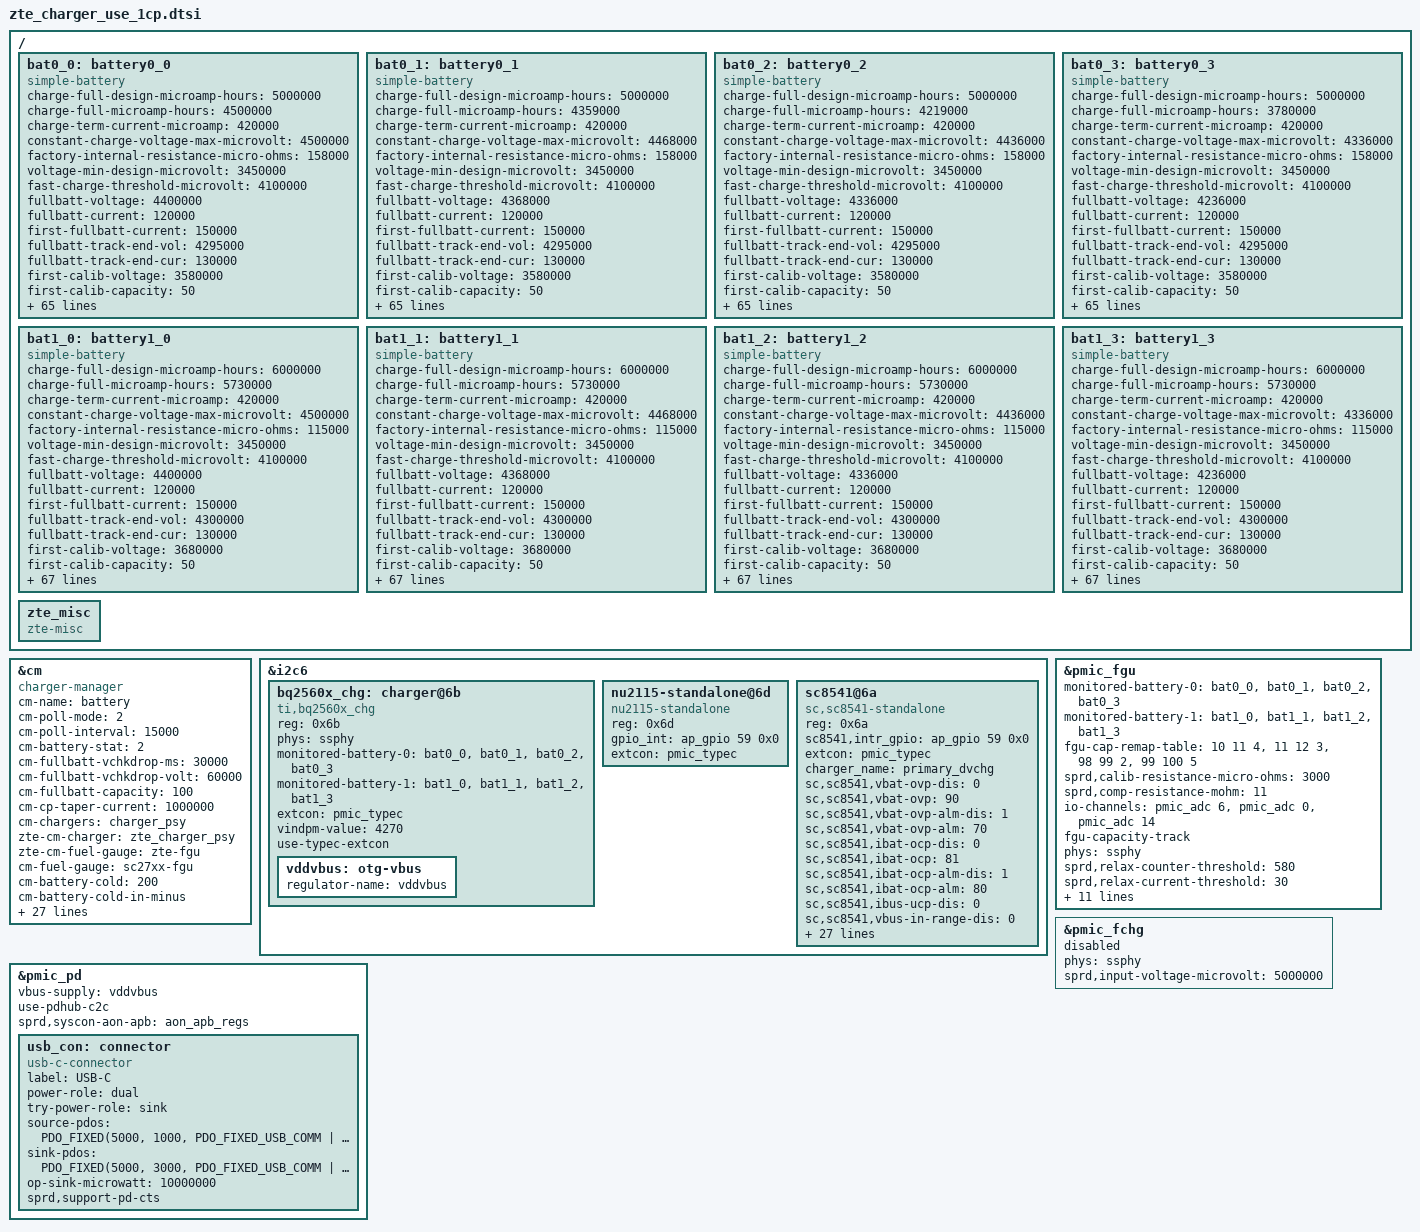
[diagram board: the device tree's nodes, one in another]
#include <dt-bindings/usb/pd.h>


/ {
	bat0_0: battery0_0 {
		compatible = "simple-battery";
		status = "okay";
		charge-full-design-microamp-hours = <5000000>;
		/*Minimum Capacity 4870*0.9 = 4383 4870*0.94 = 4558 4870*0.95 = 4626 4870*0.96 = 4675,4870*0.98 = 4772  we use *0.98 */
		charge-full-microamp-hours = <4772000>;
		charge-term-current-microamp = <420000>;
		constant-charge-voltage-max-microvolt = <4400000>;
		factory-internal-resistance-micro-ohms = <225000>;
		voltage-min-design-microvolt = <3450000>;

		fast-charge-threshold-microvolt = <4100000>;
		fullbatt-voltage = <4300000>;
		fullbatt-current = <120000>;
		first-fullbatt-current = <150000>;
		fullbatt-track-end-vol = <4295000>;
		fullbatt-track-end-cur = <130000>;
		first-calib-voltage = <3580000>;
		first-calib-capacity = <50>;

		ir-cv-offset-microvolt = <100000>;
		ir-rc-micro-ohms = <20000>;
		ir-us-upper-limit-microvolt = <4500000>;

		ocv-capacity-celsius = <20>;
		ocv-capacity-table-0 = <4374000 100>, <4308000 95>, <4250000 90>,
					<4193000 85>, <4139000 80>, <4086000 75>,
					<4037000 70>, <3992000 65>, <3951000 60>,
					<3896000 55>, <3860000 50>, <3836000 45>,
					<3814000 40>, <3797000 35>, <3784000 30>,
					<3767000 25>, <3749000 20>, <3726000 15>,
					<3697000 10>, <3683000 5>, <3400000 0>;
		/* NTC 100k, Vref 1850mV, R pull-up 110K, R pull-down 1000k */
		voltage-temp-table = <1568441 750>, <1534549 800>, <1515014 850>,
					<1475819 900>, <1402274 950>, <1334550 1000>,
					<1222195 1050>, <1131821 1100>, <1035662 1150>,
					<936426 1200>, <837104 1250>, <740441 1300>,
					<648801 1350>, <563916 1400>, <486937 1450>,
					<418193 1500>, <357806 1550>, <305304 1600>,
					<260067 1650>, <221438 1700>, <188468 1750>;
		capacity-temp-table = <25 100>, <10 100>, <0 97>, <(-10) 89>, <(-20) 57>;
		resistance-temp-table = <25 100>, <10 332>, <0 507>, <(-10) 569>, <(-20) 675>;
		charge-sdp-current-microamp = <700000 500000>;
		charge-dcp-current-microamp = <2000000 3000000>;
		charge-cdp-current-microamp = <1500000 1500000>;
		charge-unknown-current-microamp = <1000000 1000000>;
		charge-fchg-current-microamp = <3400000 2000000>;
		charge-flash-current-microamp = <3400000 2700000>;

		cap-calib-energy-density-ocv-table = <3350000 3800000>, <4150000 4350000>;
		cap-track-energy-density-ocv-table = <3400000 3722000>;

		dcp-jeita-temp-table = <1000 1030 0 4400000>,
					<1050 1080 1400000 4400000>,
					<1100 1180 1400000 4400000>,
					<1450 1420 3400000 4400000>,
					<1550 1520 2400000 4100000>;
		sdp-jeita-temp-table = <1000 1030 0 4400000>,
					<1050 1080 1400000 4400000>,
					<1100 1180 1400000 4400000>,
					<1450 1420 3400000 4400000>,
					<1550 1520 2400000 4100000>;
		cdp-jeita-temp-table = <1000 1030 0 4400000>,
					<1050 1080 1400000 4400000>,
					<1100 1180 1400000 4400000>,
					<1450 1420 3400000 4400000>,
					<1550 1520 2400000 4100000>;
		unknown-jeita-temp-table = <1000 1030 0 4400000>,
					<1050 1080 1400000 4400000>,
					<1100 1180 1400000 4400000>,
					<1450 1420 3400000 4400000>,
					<1550 1520 2400000 4100000>;
		fchg-jeita-temp-table = <1000 1030 0 4400000>,
					<1050 1080 1400000 4400000>,
					<1100 1180 1400000 4400000>,
					<1450 1420 3400000 4400000>,
					<1550 1520 2400000 4100000>;
		flash-jeita-temp-table = <1000 1030 0 4400000>,
					<1050 1080 1400000 4400000>,
					<1100 1180 1400000 4400000>,
					<1450 1420 3400000 4400000>,
					<1550 1520 2400000 4100000>;
	};

	bat0_1: battery0_1 {
		compatible = "simple-battery";
		status = "okay";
		charge-full-design-microamp-hours = <5000000>;
		/*Minimum Capacity 4870*0.9 = 4383 4870*0.94 = 4558 4870*0.95 = 4626 4870*0.96 = 4675,4870*0.98 = 4772  we use *0.98 */
		charge-full-microamp-hours = <4772000>;
		charge-term-current-microamp = <420000>;
		constant-charge-voltage-max-microvolt = <4400000>;
		factory-internal-resistance-micro-ohms = <225000>;
		voltage-min-design-microvolt = <3450000>;

		fast-charge-threshold-microvolt = <4100000>;
		fullbatt-voltage = <4300000>;
		fullbatt-current = <120000>;
		first-fullbatt-current = <150000>;
		fullbatt-track-end-vol = <4295000>;
		fullbatt-track-end-cur = <130000>;
		first-calib-voltage = <3580000>;
		first-calib-capacity = <50>;

		ir-cv-offset-microvolt = <100000>;
		ir-rc-micro-ohms = <20000>;
		ir-us-upper-limit-microvolt = <4500000>;

		ocv-capacity-celsius = <20>;
		ocv-capacity-table-0 = <4374000 100>, <4308000 95>, <4250000 90>,
					<4193000 85>, <4139000 80>, <4086000 75>,
					<4037000 70>, <3992000 65>, <3951000 60>,
					<3896000 55>, <3860000 50>, <3836000 45>,
					<3814000 40>, <3797000 35>, <3784000 30>,
					<3767000 25>, <3749000 20>, <3726000 15>,
					<3697000 10>, <3683000 5>, <3400000 0>;
		/* NTC 100k, Vref 1850mV, R pull-up 110K, R pull-down 1000k */
		voltage-temp-table = <1568441 750>, <1534549 800>, <1515014 850>,
					<1475819 900>, <1402274 950>, <1334550 1000>,
					<1222195 1050>, <1131821 1100>, <1035662 1150>,
					<936426 1200>, <837104 1250>, <740441 1300>,
					<648801 1350>, <563916 1400>, <486937 1450>,
					<418193 1500>, <357806 1550>, <305304 1600>,
					<260067 1650>, <221438 1700>, <188468 1750>;
		capacity-temp-table = <25 100>, <10 100>, <0 97>, <(-10) 89>, <(-20) 57>;
		resistance-temp-table = <25 100>, <10 332>, <0 507>, <(-10) 569>, <(-20) 675>;
		charge-sdp-current-microamp = <700000 500000>;
		charge-dcp-current-microamp = <2000000 3000000>;
		charge-cdp-current-microamp = <1500000 1500000>;
		charge-unknown-current-microamp = <1000000 1000000>;
		charge-fchg-current-microamp = <3400000 2000000>;
		charge-flash-current-microamp = <3400000 2700000>;

		cap-calib-energy-density-ocv-table = <3350000 3800000>, <4150000 4350000>;
		cap-track-energy-density-ocv-table = <3400000 3722000>;

		dcp-jeita-temp-table = <1000 1030 0 4400000>,
					<1050 1080 1400000 4400000>,
					<1100 1180 1400000 4400000>,
					<1450 1420 3400000 4400000>,
					<1550 1520 2400000 4100000>;
		sdp-jeita-temp-table = <1000 1030 0 4400000>,
					<1050 1080 1400000 4400000>,
					<1100 1180 1400000 4400000>,
					<1450 1420 3400000 4400000>,
					<1550 1520 2400000 4100000>;
		cdp-jeita-temp-table = <1000 1030 0 4400000>,
					<1050 1080 1400000 4400000>,
					<1100 1180 1400000 4400000>,
					<1450 1420 3400000 4400000>,
					<1550 1520 2400000 4100000>;
		unknown-jeita-temp-table = <1000 1030 0 4400000>,
					<1050 1080 1400000 4400000>,
					<1100 1180 1400000 4400000>,
					<1450 1420 3400000 4400000>,
					<1550 1520 2400000 4100000>;
		fchg-jeita-temp-table = <1000 1030 0 4400000>,
					<1050 1080 1400000 4400000>,
					<1100 1180 1400000 4400000>,
					<1450 1420 3400000 4400000>,
					<1550 1520 2400000 4100000>;
		flash-jeita-temp-table = <1000 1030 0 4400000>,
					<1050 1080 1400000 4400000>,
					<1100 1180 1400000 4400000>,
					<1450 1420 3400000 4400000>,
					<1550 1520 2400000 4100000>;
	};

	bat0_2: battery0_2 {
		compatible = "simple-battery";
		status = "okay";
		charge-full-design-microamp-hours = <5000000>;
		/*Minimum Capacity 4870*0.9 = 4383 4870*0.94 = 4558 4870*0.95 = 4626 4870*0.96 = 4675,4870*0.98 = 4772  we use *0.98 */
		charge-full-microamp-hours = <4772000>;
		charge-term-current-microamp = <420000>;
		constant-charge-voltage-max-microvolt = <4400000>;
		factory-internal-resistance-micro-ohms = <225000>;
		voltage-min-design-microvolt = <3450000>;

		fast-charge-threshold-microvolt = <4100000>;
		fullbatt-voltage = <4300000>;
		fullbatt-current = <120000>;
		first-fullbatt-current = <150000>;
		fullbatt-track-end-vol = <4295000>;
		fullbatt-track-end-cur = <130000>;
		first-calib-voltage = <3580000>;
		first-calib-capacity = <50>;

		ir-cv-offset-microvolt = <100000>;
		ir-rc-micro-ohms = <20000>;
		ir-us-upper-limit-microvolt = <4500000>;

		ocv-capacity-celsius = <20>;
		ocv-capacity-table-0 = <4374000 100>, <4308000 95>, <4250000 90>,
					<4193000 85>, <4139000 80>, <4086000 75>,
					<4037000 70>, <3992000 65>, <3951000 60>,
					<3896000 55>, <3860000 50>, <3836000 45>,
					<3814000 40>, <3797000 35>, <3784000 30>,
					<3767000 25>, <3749000 20>, <3726000 15>,
					<3697000 10>, <3683000 5>, <3400000 0>;
		/* NTC 100k, Vref 1850mV, R pull-up 110K, R pull-down 1000k */
		voltage-temp-table = <1568441 750>, <1534549 800>, <1515014 850>,
					<1475819 900>, <1402274 950>, <1334550 1000>,
					<1222195 1050>, <1131821 1100>, <1035662 1150>,
					<936426 1200>, <837104 1250>, <740441 1300>,
					<648801 1350>, <563916 1400>, <486937 1450>,
					<418193 1500>, <357806 1550>, <305304 1600>,
					<260067 1650>, <221438 1700>, <188468 1750>;
		capacity-temp-table = <25 100>, <10 100>, <0 97>, <(-10) 89>, <(-20) 57>;
		resistance-temp-table = <25 100>, <10 332>, <0 507>, <(-10) 569>, <(-20) 675>;
		charge-sdp-current-microamp = <700000 500000>;
		charge-dcp-current-microamp = <2000000 3000000>;
		charge-cdp-current-microamp = <1500000 1500000>;
		charge-unknown-current-microamp = <1000000 1000000>;
		charge-fchg-current-microamp = <3400000 2000000>;
		charge-flash-current-microamp = <3400000 2700000>;

		cap-calib-energy-density-ocv-table = <3350000 3800000>, <4150000 4350000>;
		cap-track-energy-density-ocv-table = <3400000 3722000>;

		dcp-jeita-temp-table = <1000 1030 0 4400000>,
					<1050 1080 1400000 4400000>,
					<1100 1180 1400000 4400000>,
					<1450 1420 3400000 4400000>,
					<1550 1520 2400000 4100000>;
		sdp-jeita-temp-table = <1000 1030 0 4400000>,
					<1050 1080 1400000 4400000>,
					<1100 1180 1400000 4400000>,
					<1450 1420 3400000 4400000>,
					<1550 1520 2400000 4100000>;
		cdp-jeita-temp-table = <1000 1030 0 4400000>,
					<1050 1080 1400000 4400000>,
					<1100 1180 1400000 4400000>,
					<1450 1420 3400000 4400000>,
					<1550 1520 2400000 4100000>;
		unknown-jeita-temp-table = <1000 1030 0 4400000>,
					<1050 1080 1400000 4400000>,
					<1100 1180 1400000 4400000>,
					<1450 1420 3400000 4400000>,
					<1550 1520 2400000 4100000>;
		fchg-jeita-temp-table = <1000 1030 0 4400000>,
					<1050 1080 1400000 4400000>,
					<1100 1180 1400000 4400000>,
					<1450 1420 3400000 4400000>,
					<1550 1520 2400000 4100000>;
		flash-jeita-temp-table = <1000 1030 0 4400000>,
					<1050 1080 1400000 4400000>,
					<1100 1180 1400000 4400000>,
					<1450 1420 3400000 4400000>,
					<1550 1520 2400000 4100000>;
	};

	bat0_3: battery0_3 {
		compatible = "simple-battery";
		status = "okay";
		charge-full-design-microamp-hours = <5000000>;
		/*Minimum Capacity 4870*0.9 = 4383 4870*0.94 = 4558 4870*0.95 = 4626 4870*0.96 = 4675,4870*0.98 = 4772  we use *0.98 */
		charge-full-microamp-hours = <4772000>;
		charge-term-current-microamp = <420000>;
		constant-charge-voltage-max-microvolt = <4400000>;
		factory-internal-resistance-micro-ohms = <225000>;
		voltage-min-design-microvolt = <3450000>;

		fast-charge-threshold-microvolt = <4100000>;
		fullbatt-voltage = <4300000>;
		fullbatt-current = <120000>;
		first-fullbatt-current = <150000>;
		fullbatt-track-end-vol = <4295000>;
		fullbatt-track-end-cur = <130000>;
		first-calib-voltage = <3580000>;
		first-calib-capacity = <50>;

		ir-cv-offset-microvolt = <100000>;
		ir-rc-micro-ohms = <20000>;
		ir-us-upper-limit-microvolt = <4500000>;

		ocv-capacity-celsius = <20>;
		ocv-capacity-table-0 = <4374000 100>, <4308000 95>, <4250000 90>,
					<4193000 85>, <4139000 80>, <4086000 75>,
					<4037000 70>, <3992000 65>, <3951000 60>,
					<3896000 55>, <3860000 50>, <3836000 45>,
					<3814000 40>, <3797000 35>, <3784000 30>,
					<3767000 25>, <3749000 20>, <3726000 15>,
					<3697000 10>, <3683000 5>, <3400000 0>;
		/* NTC 100k, Vref 1850mV, R pull-up 110K, R pull-down 1000k */
		voltage-temp-table = <1568441 750>, <1534549 800>, <1515014 850>,
					<1475819 900>, <1402274 950>, <1334550 1000>,
					<1222195 1050>, <1131821 1100>, <1035662 1150>,
					<936426 1200>, <837104 1250>, <740441 1300>,
					<648801 1350>, <563916 1400>, <486937 1450>,
					<418193 1500>, <357806 1550>, <305304 1600>,
					<260067 1650>, <221438 1700>, <188468 1750>;
		capacity-temp-table = <25 100>, <10 100>, <0 97>, <(-10) 89>, <(-20) 57>;
		resistance-temp-table = <25 100>, <10 332>, <0 507>, <(-10) 569>, <(-20) 675>;
		charge-sdp-current-microamp = <700000 500000>;
		charge-dcp-current-microamp = <2000000 3000000>;
		charge-cdp-current-microamp = <1500000 1500000>;
		charge-unknown-current-microamp = <1000000 1000000>;
		charge-fchg-current-microamp = <3400000 2000000>;
		charge-flash-current-microamp = <3400000 2700000>;

		cap-calib-energy-density-ocv-table = <3350000 3800000>, <4150000 4350000>;
		cap-track-energy-density-ocv-table = <3400000 3722000>;

		dcp-jeita-temp-table = <1000 1030 0 4400000>,
					<1050 1080 1400000 4400000>,
					<1100 1180 1400000 4400000>,
					<1450 1420 3400000 4400000>,
					<1550 1520 2400000 4100000>;
		sdp-jeita-temp-table = <1000 1030 0 4400000>,
					<1050 1080 1400000 4400000>,
					<1100 1180 1400000 4400000>,
					<1450 1420 3400000 4400000>,
					<1550 1520 2400000 4100000>;
		cdp-jeita-temp-table = <1000 1030 0 4400000>,
					<1050 1080 1400000 4400000>,
					<1100 1180 1400000 4400000>,
					<1450 1420 3400000 4400000>,
					<1550 1520 2400000 4100000>;
		unknown-jeita-temp-table = <1000 1030 0 4400000>,
					<1050 1080 1400000 4400000>,
					<1100 1180 1400000 4400000>,
					<1450 1420 3400000 4400000>,
					<1550 1520 2400000 4100000>;
		fchg-jeita-temp-table = <1000 1030 0 4400000>,
					<1050 1080 1400000 4400000>,
					<1100 1180 1400000 4400000>,
					<1450 1420 3400000 4400000>,
					<1550 1520 2400000 4100000>;
		flash-jeita-temp-table = <1000 1030 0 4400000>,
					<1050 1080 1400000 4400000>,
					<1100 1180 1400000 4400000>,
					<1450 1420 3400000 4400000>,
					<1550 1520 2400000 4100000>;
	};

	bat1_0: battery1_0 {
		compatible = "simple-battery";
		status = "okay";
		charge-full-design-microamp-hours = <5000000>;
		/*Minimum Capacity 4870*0.9 = 4383 4870*0.94 = 4558 4870*0.95 = 4626 4870*0.96 = 4675,4870*0.98 = 4772  we use *0.98 */
		charge-full-microamp-hours = <4772000>;
		charge-term-current-microamp = <420000>;
		constant-charge-voltage-max-microvolt = <4400000>;
		factory-internal-resistance-micro-ohms = <225000>;
		voltage-min-design-microvolt = <3450000>;

		fast-charge-threshold-microvolt = <4100000>;
		fullbatt-voltage = <4300000>;
		fullbatt-current = <120000>;
		first-fullbatt-current = <150000>;
		fullbatt-track-end-vol = <4295000>;
		fullbatt-track-end-cur = <130000>;
		first-calib-voltage = <3580000>;
		first-calib-capacity = <50>;

		ir-cv-offset-microvolt = <100000>;
		ir-rc-micro-ohms = <20000>;
		ir-us-upper-limit-microvolt = <4500000>;

		ocv-capacity-celsius = <20>;
		ocv-capacity-table-0 = <4374000 100>, <4308000 95>, <4250000 90>,
					<4193000 85>, <4139000 80>, <4086000 75>,
					<4037000 70>, <3992000 65>, <3951000 60>,
					<3896000 55>, <3860000 50>, <3836000 45>,
					<3814000 40>, <3797000 35>, <3784000 30>,
					<3767000 25>, <3749000 20>, <3726000 15>,
					<3697000 10>, <3683000 5>, <3400000 0>;
		/* NTC 100k, Vref 1850mV, R pull-up 110K, R pull-down 1000k */
		voltage-temp-table = <1568441 750>, <1534549 800>, <1515014 850>,
					<1475819 900>, <1402274 950>, <1334550 1000>,
					<1222195 1050>, <1131821 1100>, <1035662 1150>,
					<936426 1200>, <837104 1250>, <740441 1300>,
					<648801 1350>, <563916 1400>, <486937 1450>,
					<418193 1500>, <357806 1550>, <305304 1600>,
					<260067 1650>, <221438 1700>, <188468 1750>;
		capacity-temp-table = <25 100>, <10 100>, <0 97>, <(-10) 89>, <(-20) 57>;
		resistance-temp-table = <25 100>, <10 332>, <0 507>, <(-10) 569>, <(-20) 675>;
		charge-sdp-current-microamp = <700000 500000>;
		charge-dcp-current-microamp = <2000000 3000000>;
		charge-cdp-current-microamp = <1500000 1500000>;
		charge-unknown-current-microamp = <1000000 1000000>;
		charge-fchg-current-microamp = <3400000 2000000>;
		charge-flash-current-microamp = <3400000 2700000>;

		cap-calib-energy-density-ocv-table = <3350000 3800000>, <4150000 4350000>;
		cap-track-energy-density-ocv-table = <3400000 3722000>;

		dcp-jeita-temp-table = <1000 1030 0 4400000>,
					<1050 1080 1400000 4400000>,
					<1100 1180 1400000 4400000>,
					<1450 1420 3400000 4400000>,
					<1550 1520 2400000 4100000>;
		sdp-jeita-temp-table = <1000 1030 0 4400000>,
					<1050 1080 1400000 4400000>,
					<1100 1180 1400000 4400000>,
					<1450 1420 3400000 4400000>,
					<1550 1520 2400000 4100000>;
		cdp-jeita-temp-table = <1000 1030 0 4400000>,
					<1050 1080 1400000 4400000>,
					<1100 1180 1400000 4400000>,
					<1450 1420 3400000 4400000>,
					<1550 1520 2400000 4100000>;
		unknown-jeita-temp-table = <1000 1030 0 4400000>,
					<1050 1080 1400000 4400000>,
					<1100 1180 1400000 4400000>,
					<1450 1420 3400000 4400000>,
					<1550 1520 2400000 4100000>;
		fchg-jeita-temp-table = <1000 1030 0 4400000>,
					<1050 1080 1400000 4400000>,
					<1100 1180 1400000 4400000>,
					<1450 1420 3400000 4400000>,
					<1550 1520 2400000 4100000>;
		flash-jeita-temp-table = <1000 1030 0 4400000>,
					<1050 1080 1400000 4400000>,
					<1100 1180 1400000 4400000>,
					<1450 1420 3400000 4400000>,
					<1550 1520 2400000 4100000>;
	};

	bat1_1: battery1_1 {
		compatible = "simple-battery";
		status = "okay";
		charge-full-design-microamp-hours = <5000000>;
		/*Minimum Capacity 4870*0.9 = 4383 4870*0.94 = 4558 4870*0.95 = 4626 4870*0.96 = 4675,4870*0.98 = 4772  we use *0.98 */
		charge-full-microamp-hours = <4772000>;
		charge-term-current-microamp = <420000>;
		constant-charge-voltage-max-microvolt = <4400000>;
		factory-internal-resistance-micro-ohms = <225000>;
		voltage-min-design-microvolt = <3450000>;

		fast-charge-threshold-microvolt = <4100000>;
		fullbatt-voltage = <4300000>;
		fullbatt-current = <120000>;
		first-fullbatt-current = <150000>;
		fullbatt-track-end-vol = <4295000>;
		fullbatt-track-end-cur = <130000>;
		first-calib-voltage = <3580000>;
		first-calib-capacity = <50>;

		ir-cv-offset-microvolt = <100000>;
		ir-rc-micro-ohms = <20000>;
		ir-us-upper-limit-microvolt = <4500000>;

		ocv-capacity-celsius = <20>;
		ocv-capacity-table-0 = <4374000 100>, <4308000 95>, <4250000 90>,
					<4193000 85>, <4139000 80>, <4086000 75>,
					<4037000 70>, <3992000 65>, <3951000 60>,
					<3896000 55>, <3860000 50>, <3836000 45>,
					<3814000 40>, <3797000 35>, <3784000 30>,
					<3767000 25>, <3749000 20>, <3726000 15>,
					<3697000 10>, <3683000 5>, <3400000 0>;
		/* NTC 100k, Vref 1850mV, R pull-up 110K, R pull-down 1000k */
		voltage-temp-table = <1568441 750>, <1534549 800>, <1515014 850>,
					<1475819 900>, <1402274 950>, <1334550 1000>,
					<1222195 1050>, <1131821 1100>, <1035662 1150>,
					<936426 1200>, <837104 1250>, <740441 1300>,
					<648801 1350>, <563916 1400>, <486937 1450>,
					<418193 1500>, <357806 1550>, <305304 1600>,
					<260067 1650>, <221438 1700>, <188468 1750>;
		capacity-temp-table = <25 100>, <10 100>, <0 97>, <(-10) 89>, <(-20) 57>;
		resistance-temp-table = <25 100>, <10 332>, <0 507>, <(-10) 569>, <(-20) 675>;
		charge-sdp-current-microamp = <700000 500000>;
		charge-dcp-current-microamp = <2000000 3000000>;
		charge-cdp-current-microamp = <1500000 1500000>;
		charge-unknown-current-microamp = <1000000 1000000>;
		charge-fchg-current-microamp = <3400000 2000000>;
		charge-flash-current-microamp = <3400000 2700000>;

		cap-calib-energy-density-ocv-table = <3350000 3800000>, <4150000 4350000>;
		cap-track-energy-density-ocv-table = <3400000 3722000>;

		dcp-jeita-temp-table = <1000 1030 0 4400000>,
					<1050 1080 1400000 4400000>,
					<1100 1180 1400000 4400000>,
					<1450 1420 3400000 4400000>,
					<1550 1520 2400000 4100000>;
		sdp-jeita-temp-table = <1000 1030 0 4400000>,
					<1050 1080 1400000 4400000>,
					<1100 1180 1400000 4400000>,
					<1450 1420 3400000 4400000>,
					<1550 1520 2400000 4100000>;
		cdp-jeita-temp-table = <1000 1030 0 4400000>,
					<1050 1080 1400000 4400000>,
					<1100 1180 1400000 4400000>,
					<1450 1420 3400000 4400000>,
					<1550 1520 2400000 4100000>;
		unknown-jeita-temp-table = <1000 1030 0 4400000>,
					<1050 1080 1400000 4400000>,
					<1100 1180 1400000 4400000>,
					<1450 1420 3400000 4400000>,
					<1550 1520 2400000 4100000>;
		fchg-jeita-temp-table = <1000 1030 0 4400000>,
					<1050 1080 1400000 4400000>,
					<1100 1180 1400000 4400000>,
					<1450 1420 3400000 4400000>,
					<1550 1520 2400000 4100000>;
		flash-jeita-temp-table = <1000 1030 0 4400000>,
					<1050 1080 1400000 4400000>,
					<1100 1180 1400000 4400000>,
					<1450 1420 3400000 4400000>,
					<1550 1520 2400000 4100000>;
	};

	bat1_2: battery1_2 {
		compatible = "simple-battery";
		status = "okay";
		charge-full-design-microamp-hours = <5000000>;
		/*Minimum Capacity 4870*0.9 = 4383 4870*0.94 = 4558 4870*0.95 = 4626 4870*0.96 = 4675,4870*0.98 = 4772  we use *0.98 */
		charge-full-microamp-hours = <4772000>;
		charge-term-current-microamp = <420000>;
		constant-charge-voltage-max-microvolt = <4400000>;
		factory-internal-resistance-micro-ohms = <225000>;
		voltage-min-design-microvolt = <3450000>;

		fast-charge-threshold-microvolt = <4100000>;
		fullbatt-voltage = <4300000>;
		fullbatt-current = <120000>;
		first-fullbatt-current = <150000>;
		fullbatt-track-end-vol = <4295000>;
		fullbatt-track-end-cur = <130000>;
		first-calib-voltage = <3580000>;
		first-calib-capacity = <50>;

		ir-cv-offset-microvolt = <100000>;
		ir-rc-micro-ohms = <20000>;
		ir-us-upper-limit-microvolt = <4500000>;

		ocv-capacity-celsius = <20>;
		ocv-capacity-table-0 = <4374000 100>, <4308000 95>, <4250000 90>,
					<4193000 85>, <4139000 80>, <4086000 75>,
					<4037000 70>, <3992000 65>, <3951000 60>,
					<3896000 55>, <3860000 50>, <3836000 45>,
					<3814000 40>, <3797000 35>, <3784000 30>,
					<3767000 25>, <3749000 20>, <3726000 15>,
					<3697000 10>, <3683000 5>, <3400000 0>;
		/* NTC 100k, Vref 1850mV, R pull-up 110K, R pull-down 1000k */
		voltage-temp-table = <1568441 750>, <1534549 800>, <1515014 850>,
					<1475819 900>, <1402274 950>, <1334550 1000>,
					<1222195 1050>, <1131821 1100>, <1035662 1150>,
					<936426 1200>, <837104 1250>, <740441 1300>,
					<648801 1350>, <563916 1400>, <486937 1450>,
					<418193 1500>, <357806 1550>, <305304 1600>,
					<260067 1650>, <221438 1700>, <188468 1750>;
		capacity-temp-table = <25 100>, <10 100>, <0 97>, <(-10) 89>, <(-20) 57>;
		resistance-temp-table = <25 100>, <10 332>, <0 507>, <(-10) 569>, <(-20) 675>;
		charge-sdp-current-microamp = <700000 500000>;
		charge-dcp-current-microamp = <2000000 3000000>;
		charge-cdp-current-microamp = <1500000 1500000>;
		charge-unknown-current-microamp = <1000000 1000000>;
		charge-fchg-current-microamp = <3400000 2000000>;
		charge-flash-current-microamp = <3400000 2700000>;

		cap-calib-energy-density-ocv-table = <3350000 3800000>, <4150000 4350000>;
		cap-track-energy-density-ocv-table = <3400000 3722000>;

		dcp-jeita-temp-table = <1000 1030 0 4400000>,
					<1050 1080 1400000 4400000>,
					<1100 1180 1400000 4400000>,
					<1450 1420 3400000 4400000>,
					<1550 1520 2400000 4100000>;
		sdp-jeita-temp-table = <1000 1030 0 4400000>,
					<1050 1080 1400000 4400000>,
					<1100 1180 1400000 4400000>,
					<1450 1420 3400000 4400000>,
					<1550 1520 2400000 4100000>;
		cdp-jeita-temp-table = <1000 1030 0 4400000>,
					<1050 1080 1400000 4400000>,
					<1100 1180 1400000 4400000>,
					<1450 1420 3400000 4400000>,
					<1550 1520 2400000 4100000>;
		unknown-jeita-temp-table = <1000 1030 0 4400000>,
					<1050 1080 1400000 4400000>,
					<1100 1180 1400000 4400000>,
					<1450 1420 3400000 4400000>,
					<1550 1520 2400000 4100000>;
		fchg-jeita-temp-table = <1000 1030 0 4400000>,
					<1050 1080 1400000 4400000>,
					<1100 1180 1400000 4400000>,
					<1450 1420 3400000 4400000>,
					<1550 1520 2400000 4100000>;
		flash-jeita-temp-table = <1000 1030 0 4400000>,
					<1050 1080 1400000 4400000>,
					<1100 1180 1400000 4400000>,
					<1450 1420 3400000 4400000>,
					<1550 1520 2400000 4100000>;
	};

	bat1_3: battery1_3 {
		compatible = "simple-battery";
		status = "okay";
		charge-full-design-microamp-hours = <5000000>;
		/*Minimum Capacity 4870*0.9 = 4383 4870*0.94 = 4558 4870*0.95 = 4626 4870*0.96 = 4675,4870*0.98 = 4772  we use *0.98 */
		charge-full-microamp-hours = <4772000>;
		charge-term-current-microamp = <420000>;
		constant-charge-voltage-max-microvolt = <4400000>;
		factory-internal-resistance-micro-ohms = <225000>;
		voltage-min-design-microvolt = <3450000>;

		fast-charge-threshold-microvolt = <4100000>;
		fullbatt-voltage = <4300000>;
		fullbatt-current = <120000>;
		first-fullbatt-current = <150000>;
		fullbatt-track-end-vol = <4295000>;
		fullbatt-track-end-cur = <130000>;
		first-calib-voltage = <3580000>;
		first-calib-capacity = <50>;

		ir-cv-offset-microvolt = <100000>;
		ir-rc-micro-ohms = <20000>;
		ir-us-upper-limit-microvolt = <4500000>;

		ocv-capacity-celsius = <20>;
		ocv-capacity-table-0 = <4374000 100>, <4308000 95>, <4250000 90>,
					<4193000 85>, <4139000 80>, <4086000 75>,
					<4037000 70>, <3992000 65>, <3951000 60>,
					<3896000 55>, <3860000 50>, <3836000 45>,
					<3814000 40>, <3797000 35>, <3784000 30>,
					<3767000 25>, <3749000 20>, <3726000 15>,
					<3697000 10>, <3683000 5>, <3400000 0>;
		/* NTC 100k, Vref 1850mV, R pull-up 110K, R pull-down 1000k */
		voltage-temp-table = <1568441 750>, <1534549 800>, <1515014 850>,
					<1475819 900>, <1402274 950>, <1334550 1000>,
					<1222195 1050>, <1131821 1100>, <1035662 1150>,
					<936426 1200>, <837104 1250>, <740441 1300>,
					<648801 1350>, <563916 1400>, <486937 1450>,
					<418193 1500>, <357806 1550>, <305304 1600>,
					<260067 1650>, <221438 1700>, <188468 1750>;
		capacity-temp-table = <25 100>, <10 100>, <0 97>, <(-10) 89>, <(-20) 57>;
		resistance-temp-table = <25 100>, <10 332>, <0 507>, <(-10) 569>, <(-20) 675>;
		charge-sdp-current-microamp = <700000 500000>;
		charge-dcp-current-microamp = <2000000 3000000>;
		charge-cdp-current-microamp = <1500000 1500000>;
		charge-unknown-current-microamp = <1000000 1000000>;
		charge-fchg-current-microamp = <3400000 2000000>;
		charge-flash-current-microamp = <3400000 2700000>;

		cap-calib-energy-density-ocv-table = <3350000 3800000>, <4150000 4350000>;
		cap-track-energy-density-ocv-table = <3400000 3722000>;

		dcp-jeita-temp-table = <1000 1030 0 4400000>,
					<1050 1080 1400000 4400000>,
					<1100 1180 1400000 4400000>,
					<1450 1420 3400000 4400000>,
					<1550 1520 2400000 4100000>;
		sdp-jeita-temp-table = <1000 1030 0 4400000>,
					<1050 1080 1400000 4400000>,
					<1100 1180 1400000 4400000>,
					<1450 1420 3400000 4400000>,
					<1550 1520 2400000 4100000>;
		cdp-jeita-temp-table = <1000 1030 0 4400000>,
					<1050 1080 1400000 4400000>,
					<1100 1180 1400000 4400000>,
					<1450 1420 3400000 4400000>,
					<1550 1520 2400000 4100000>;
		unknown-jeita-temp-table = <1000 1030 0 4400000>,
					<1050 1080 1400000 4400000>,
					<1100 1180 1400000 4400000>,
					<1450 1420 3400000 4400000>,
					<1550 1520 2400000 4100000>;
		fchg-jeita-temp-table = <1000 1030 0 4400000>,
					<1050 1080 1400000 4400000>,
					<1100 1180 1400000 4400000>,
					<1450 1420 3400000 4400000>,
					<1550 1520 2400000 4100000>;
		flash-jeita-temp-table = <1000 1030 0 4400000>,
					<1050 1080 1400000 4400000>,
					<1100 1180 1400000 4400000>,
					<1450 1420 3400000 4400000>,
					<1550 1520 2400000 4100000>;
	};
};

&bat0_0 {
	compatible = "simple-battery";
	status = "okay";
	charge-full-design-microamp-hours = <5000000>;
	/*Minimum Capacity origin min cap is 4930, 4930*0.91 = 4500*/
	charge-full-microamp-hours = <4500000>;
	charge-term-current-microamp = <420000>;
	constant-charge-voltage-max-microvolt = <4500000>;
	factory-internal-resistance-micro-ohms = <158000>;
	voltage-min-design-microvolt = <3450000>;

	fast-charge-threshold-microvolt = <4100000>;
	fullbatt-voltage = <4400000>;
	fullbatt-current = <120000>;
	first-fullbatt-current = <150000>;
	fullbatt-track-end-vol = <4295000>;
	fullbatt-track-end-cur = <130000>;
	first-calib-voltage = <3580000>;
	first-calib-capacity = <50>;

	ir-cv-offset-microvolt = <100000>;
	ir-rc-micro-ohms = <20000>;
	ir-us-upper-limit-microvolt = <4500000>;

	batt-id-list = <110 430>;  /* kohm,  scud 5000mAh/highpower 6000mAh*/
	ocv-capacity-celsius = <20>;
	ocv-capacity-table-0 = <4425000 100>, <4368000 95>, <4315000 90>,
				<4257000 85>, <4197000 80>, <4138000 75>,
				<4083000 70>, <4032000 65>, <3985000 60>,
				<3922000 55>, <3880000 50>, <3850000 45>,
				<3827000 40>, <3808000 35>, <3792000 30>,
				<3771000 25>, <3749000 20>, <3723000 15>,
				<3692000 10>, <3682000 5>, <3400000 0>;
	/* NTC 100k, Vref 1850mV, R pull-up 110K, R pull-down 1000k */
	voltage-temp-table = <1568441 750>, <1534549 800>, <1515014 850>,
				<1475819 900>, <1402274 950>, <1334550 1000>,
				<1222195 1050>, <1131821 1100>, <1035662 1150>,
				<936426 1200>, <837104 1250>, <740441 1300>,
				<648801 1350>, <563916 1400>, <486937 1450>,
				<418193 1500>, <357806 1550>, <305304 1600>,
				<260067 1650>, <221438 1700>, <188468 1750>;
	capacity-temp-table = <25 100>, <10 100>, <0 90>, <(-10) 81>, <(-20) 62>;
	resistance-temp-table = <25 100>, <10 233>, <0 746>, <(-10) 824>, <(-20) 913>;
	charge-sdp-current-microamp = <700000 500000>;
	charge-dcp-current-microamp = <6500000 3000000>;
	charge-cdp-current-microamp = <4800000 1500000>;
	charge-unknown-current-microamp = <1000000 1000000>;
	charge-fchg-current-microamp = <6500000 4000000>;
	charge-flash-current-microamp = <6500000 4000000>;

	cap-calib-energy-density-ocv-table = <3350000 3800000>, <4150000 4400000>;
	cap-track-energy-density-ocv-table = <3400000 3722000>;

	dcp-jeita-temp-table = <1000 1030 0 4450000>,
				<1050 1080 1461000 4450000>,
				<1150 1180 4800000 4450000>,
				<1450 1420 6500000 4450000>,
				<1550 1520 2435000 4100000>;
	sdp-jeita-temp-table = <1000 1030 0 4450000>,
				<1050 1080 1461000 4450000>,
				<1150 1180 4800000 4450000>,
				<1450 1420 6500000 4450000>,
				<1550 1520 2435000 4100000>;
	cdp-jeita-temp-table = <1000 1030 0 4450000>,
				<1050 1080 1461000 4450000>,
				<1150 1180 4800000 4450000>,
				<1450 1420 6500000 4450000>,
				<1550 1520 2435000 4100000>;
	unknown-jeita-temp-table = <1000 1030 0 4450000>,
				<1050 1080 1461000 4450000>,
				<1150 1180 4800000 4450000>,
				<1450 1420 6500000 4450000>,
				<1550 1520 2435000 4100000>;

	fchg-jeita-temp-table = <1000 1030 0 4450000>,
				<1050 1080 1461000 4450000>,
				<1150 1180 4800000 4450000>,
				<1450 1420 6500000 4450000>,
				<1550 1520 2435000 4100000>;
	flash-jeita-temp-table = <1000 1030 0 4450000>,
				<1050 1080 1461000 4450000>,
				<1150 1180 4800000 4450000>,
				<1450 1420 6500000 4450000>,
				<1550 1520 2435000 4100000>;

};

&bat0_1 {
	compatible = "simple-battery";
	status = "okay";
	charge-full-design-microamp-hours = <5000000>;
	/*Minimum Capacity origin min cap is 4930, 4930*0.91 = 4500*/
	charge-full-microamp-hours = <4359000>;
	charge-term-current-microamp = <420000>;
	constant-charge-voltage-max-microvolt = <4468000>;
	factory-internal-resistance-micro-ohms = <158000>;
	voltage-min-design-microvolt = <3450000>;

	fast-charge-threshold-microvolt = <4100000>;
	fullbatt-voltage = <4368000>;
	fullbatt-current = <120000>;
	first-fullbatt-current = <150000>;
	fullbatt-track-end-vol = <4295000>;
	fullbatt-track-end-cur = <130000>;
	first-calib-voltage = <3580000>;
	first-calib-capacity = <50>;

	ir-cv-offset-microvolt = <100000>;
	ir-rc-micro-ohms = <20000>;
	ir-us-upper-limit-microvolt = <4500000>;

	batt-id-list = <110 430>;  /* kohm,  scud 5000mAh/highpower 6000mAh*/
	ocv-capacity-celsius = <20>;
	ocv-capacity-table-0 = <4393000 100>, <4338000 95>, <4286000 90>,
				<4230000 85>, <4172000 80>, <4114000 75>,
				<4061000 70>, <4012000 65>, <3966000 60>,
				<3905000 55>, <3865000 50>, <3835000 45>,
				<3813000 40>, <3795000 35>, <3779000 30>,
				<3759000 25>, <3738000 20>, <3712000 15>,
				<3682000 10>, <3663000 5>, <3400000 0>;
	/* NTC 100k, Vref 1850mV, R pull-up 110K, R pull-down 1000k */
	voltage-temp-table = <1568441 750>, <1534549 800>, <1515014 850>,
				<1475819 900>, <1402274 950>, <1334550 1000>,
				<1222195 1050>, <1131821 1100>, <1035662 1150>,
				<936426 1200>, <837104 1250>, <740441 1300>,
				<648801 1350>, <563916 1400>, <486937 1450>,
				<418193 1500>, <357806 1550>, <305304 1600>,
				<260067 1650>, <221438 1700>, <188468 1750>;
	capacity-temp-table = <25 100>, <10 100>, <0 90>, <(-10) 81>, <(-20) 62>;
	resistance-temp-table = <25 100>, <10 233>, <0 746>, <(-10) 824>, <(-20) 913>;
	charge-sdp-current-microamp = <700000 500000>;
	charge-dcp-current-microamp = <6500000 3000000>;
	charge-cdp-current-microamp = <4800000 1500000>;
	charge-unknown-current-microamp = <1000000 1000000>;
	charge-fchg-current-microamp = <6500000 4000000>;
	charge-flash-current-microamp = <6500000 4000000>;

	cap-calib-energy-density-ocv-table = <3350000 3800000>, <4150000 4400000>;
	cap-track-energy-density-ocv-table = <3400000 3722000>;

	dcp-jeita-temp-table = <1000 1030 0 4450000>,
				<1050 1080 1461000 4450000>,
				<1150 1180 4800000 4450000>,
				<1450 1420 6500000 4450000>,
				<1550 1520 2435000 4100000>;
	sdp-jeita-temp-table = <1000 1030 0 4450000>,
				<1050 1080 1461000 4450000>,
				<1150 1180 4800000 4450000>,
				<1450 1420 6500000 4450000>,
				<1550 1520 2435000 4100000>;
	cdp-jeita-temp-table = <1000 1030 0 4450000>,
				<1050 1080 1461000 4450000>,
				<1150 1180 4800000 4450000>,
				<1450 1420 6500000 4450000>,
				<1550 1520 2435000 4100000>;
	unknown-jeita-temp-table = <1000 1030 0 4450000>,
				<1050 1080 1461000 4450000>,
				<1150 1180 4800000 4450000>,
				<1450 1420 6500000 4450000>,
				<1550 1520 2435000 4100000>;

	fchg-jeita-temp-table = <1000 1030 0 4450000>,
				<1050 1080 1461000 4450000>,
				<1150 1180 4800000 4450000>,
				<1450 1420 6500000 4450000>,
				<1550 1520 2435000 4100000>;
	flash-jeita-temp-table = <1000 1030 0 4450000>,
				<1050 1080 1461000 4450000>,
				<1150 1180 4800000 4450000>,
				<1450 1420 6500000 4450000>,
				<1550 1520 2435000 4100000>;

};

&bat0_2 {
	compatible = "simple-battery";
	status = "okay";
	charge-full-design-microamp-hours = <5000000>;
	/*Minimum Capacity origin min cap is 4930, 4930*0.91 = 4500*/
	charge-full-microamp-hours = <4219000>;
	charge-term-current-microamp = <420000>;
	constant-charge-voltage-max-microvolt = <4436000>;
	factory-internal-resistance-micro-ohms = <158000>;
	voltage-min-design-microvolt = <3450000>;

	fast-charge-threshold-microvolt = <4100000>;
	fullbatt-voltage = <4336000>;
	fullbatt-current = <120000>;
	first-fullbatt-current = <150000>;
	fullbatt-track-end-vol = <4295000>;
	fullbatt-track-end-cur = <130000>;
	first-calib-voltage = <3580000>;
	first-calib-capacity = <50>;

	ir-cv-offset-microvolt = <100000>;
	ir-rc-micro-ohms = <20000>;
	ir-us-upper-limit-microvolt = <4500000>;

	batt-id-list = <110 430>;  /* kohm,  scud 5000mAh/highpower 6000mAh*/
	ocv-capacity-celsius = <20>;
	ocv-capacity-table-0 = <4361000 100>, <4307000 95>, <4257000 90>,
				<4203000 85>, <4147000 80>, <4091000 75>,
				<4040000 70>, <3992000 65>, <3948000 60>,
				<3889000 55>, <3850000 50>, <3821000 45>,
				<3800000 40>, <3782000 35>, <3767000 30>,
				<3747000 25>, <3727000 20>, <3702000 15>,
				<3673000 10>, <3664000 5>, <3400000 0>;
	/* NTC 100k, Vref 1850mV, R pull-up 110K, R pull-down 1000k */
	voltage-temp-table = <1568441 750>, <1534549 800>, <1515014 850>,
				<1475819 900>, <1402274 950>, <1334550 1000>,
				<1222195 1050>, <1131821 1100>, <1035662 1150>,
				<936426 1200>, <837104 1250>, <740441 1300>,
				<648801 1350>, <563916 1400>, <486937 1450>,
				<418193 1500>, <357806 1550>, <305304 1600>,
				<260067 1650>, <221438 1700>, <188468 1750>;
	capacity-temp-table = <25 100>, <10 100>, <0 90>, <(-10) 81>, <(-20) 62>;
	resistance-temp-table = <25 100>, <10 233>, <0 746>, <(-10) 824>, <(-20) 913>;
	charge-sdp-current-microamp = <700000 500000>;
	charge-dcp-current-microamp = <6500000 3000000>;
	charge-cdp-current-microamp = <4800000 1500000>;
	charge-unknown-current-microamp = <1000000 1000000>;
	charge-fchg-current-microamp = <6500000 4000000>;
	charge-flash-current-microamp = <6500000 4000000>;

	cap-calib-energy-density-ocv-table = <3350000 3800000>, <4150000 4400000>;
	cap-track-energy-density-ocv-table = <3400000 3722000>;

	dcp-jeita-temp-table = <1000 1030 0 4450000>,
				<1050 1080 1461000 4450000>,
				<1150 1180 4800000 4450000>,
				<1450 1420 6500000 4450000>,
				<1550 1520 2435000 4100000>;
	sdp-jeita-temp-table = <1000 1030 0 4450000>,
				<1050 1080 1461000 4450000>,
				<1150 1180 4800000 4450000>,
				<1450 1420 6500000 4450000>,
				<1550 1520 2435000 4100000>;
	cdp-jeita-temp-table = <1000 1030 0 4450000>,
				<1050 1080 1461000 4450000>,
				<1150 1180 4800000 4450000>,
				<1450 1420 6500000 4450000>,
				<1550 1520 2435000 4100000>;
	unknown-jeita-temp-table = <1000 1030 0 4450000>,
				<1050 1080 1461000 4450000>,
				<1150 1180 4800000 4450000>,
				<1450 1420 6500000 4450000>,
				<1550 1520 2435000 4100000>;

	fchg-jeita-temp-table = <1000 1030 0 4450000>,
				<1050 1080 1461000 4450000>,
				<1150 1180 4800000 4450000>,
				<1450 1420 6500000 4450000>,
				<1550 1520 2435000 4100000>;
	flash-jeita-temp-table = <1000 1030 0 4450000>,
				<1050 1080 1461000 4450000>,
				<1150 1180 4800000 4450000>,
				<1450 1420 6500000 4450000>,
				<1550 1520 2435000 4100000>;

};

&bat0_3 {
	compatible = "simple-battery";
	status = "okay";
	charge-full-design-microamp-hours = <5000000>;
	/*Minimum Capacity origin min cap is 4930, 4930*0.91 = 4500*/
	charge-full-microamp-hours = <3780000>;
	charge-term-current-microamp = <420000>;
	constant-charge-voltage-max-microvolt = <4336000>;
	factory-internal-resistance-micro-ohms = <158000>;
	voltage-min-design-microvolt = <3450000>;

	fast-charge-threshold-microvolt = <4100000>;
	fullbatt-voltage = <4236000>;
	fullbatt-current = <120000>;
	first-fullbatt-current = <150000>;
	fullbatt-track-end-vol = <4295000>;
	fullbatt-track-end-cur = <130000>;
	first-calib-voltage = <3580000>;
	first-calib-capacity = <50>;

	ir-cv-offset-microvolt = <100000>;
	ir-rc-micro-ohms = <20000>;
	ir-us-upper-limit-microvolt = <4500000>;

	batt-id-list = <110 430>;  /* kohm,  scud 5000mAh/highpower 6000mAh*/
	ocv-capacity-celsius = <20>;
	ocv-capacity-table-0 = <4261000 100>, <4213000 95>, <4168000 90>,
				<4119000 85>, <4069000 80>, <4019000 75>,
				<3973000 70>, <3930000 65>, <3891000 60>,
				<3838000 55>, <3803000 50>, <3778000 45>,
				<3758000 40>, <3742000 35>, <3729000 30>,
				<3711000 25>, <3693000 20>, <3671000 15>,
				<3645000 10>, <3636000 5>, <3400000 0>;
	/* NTC 100k, Vref 1850mV, R pull-up 110K, R pull-down 1000k */
	voltage-temp-table = <1568441 750>, <1534549 800>, <1515014 850>,
				<1475819 900>, <1402274 950>, <1334550 1000>,
				<1222195 1050>, <1131821 1100>, <1035662 1150>,
				<936426 1200>, <837104 1250>, <740441 1300>,
				<648801 1350>, <563916 1400>, <486937 1450>,
				<418193 1500>, <357806 1550>, <305304 1600>,
				<260067 1650>, <221438 1700>, <188468 1750>;
	capacity-temp-table = <25 100>, <10 100>, <0 90>, <(-10) 81>, <(-20) 62>;
	resistance-temp-table = <25 100>, <10 233>, <0 746>, <(-10) 824>, <(-20) 913>;
	charge-sdp-current-microamp = <700000 500000>;
	charge-dcp-current-microamp = <6500000 3000000>;
	charge-cdp-current-microamp = <4800000 1500000>;
	charge-unknown-current-microamp = <1000000 1000000>;
	charge-fchg-current-microamp = <6500000 4000000>;
	charge-flash-current-microamp = <6500000 4000000>;

	cap-calib-energy-density-ocv-table = <3350000 3800000>, <4150000 4400000>;
	cap-track-energy-density-ocv-table = <3400000 3722000>;

	dcp-jeita-temp-table = <1000 1030 0 4450000>,
				<1050 1080 1461000 4450000>,
				<1150 1180 4800000 4450000>,
				<1450 1420 6500000 4450000>,
				<1550 1520 2435000 4100000>;
	sdp-jeita-temp-table = <1000 1030 0 4450000>,
				<1050 1080 1461000 4450000>,
				<1150 1180 4800000 4450000>,
				<1450 1420 6500000 4450000>,
				<1550 1520 2435000 4100000>;
	cdp-jeita-temp-table = <1000 1030 0 4450000>,
				<1050 1080 1461000 4450000>,
				<1150 1180 4800000 4450000>,
				<1450 1420 6500000 4450000>,
				<1550 1520 2435000 4100000>;
	unknown-jeita-temp-table = <1000 1030 0 4450000>,
				<1050 1080 1461000 4450000>,
				<1150 1180 4800000 4450000>,
				<1450 1420 6500000 4450000>,
				<1550 1520 2435000 4100000>;

	fchg-jeita-temp-table = <1000 1030 0 4450000>,
				<1050 1080 1461000 4450000>,
				<1150 1180 4800000 4450000>,
				<1450 1420 6500000 4450000>,
				<1550 1520 2435000 4100000>;
	flash-jeita-temp-table = <1000 1030 0 4450000>,
				<1050 1080 1461000 4450000>,
				<1150 1180 4800000 4450000>,
				<1450 1420 6500000 4450000>,
				<1550 1520 2435000 4100000>;

};

&bat1_0 {
	compatible = "simple-battery";
	status = "okay";
	charge-term-current-microamp = <420000>;
	constant-charge-voltage-max-microvolt = <4500000>;
	constant-charge-current-max-microamp = <4600000>;
	factory-internal-resistance-micro-ohms = <115000>;
	voltage-min-design-microvolt = <3450000>;
	fast-charge-threshold-microvolt = <4100000>;
	fullbatt-voltage = <4400000>;		/* minus 100mV */
	fullbatt-current = <120000>;		/* not used */
	first-fullbatt-current = <150000>;
	fullbatt-track-end-vol = <4300000>;
	fullbatt-track-end-cur = <130000>;
	first-calib-voltage = <3680000>;
	first-calib-capacity = <50>;

	ir-cv-offset-microvolt = <100000>;
	ir-rc-micro-ohms = <20000>;
	ir-us-upper-limit-microvolt = <4500000>;

	batt-id-list = <110 430>;  /* kohm,  scud 5000mAh/highpower 6000mAh*/
	batt-id-ref-vol = <1875>; /* mV */
	charge-full-design-microamp-hours = <6000000>;
	/*Minimum Capacity 5880*0.96 = 5820,we use *0.975 */
	charge-full-microamp-hours = <5730000>;

	ocv-capacity-celsius = <25>;
	ocv-capacity-table-0 = <4445000 100>, <4386000 95>, <4335000 90>,
				<4277000 85>, <4216000 80>, <4155000 75>,
				<4097000 70>, <4044000 65>, <3996000 60>,
				<3941000 55>, <3886000 50>, <3855000 45>,
				<3830000 40>, <3809000 35>, <3793000 30>,
				<3775000 25>, <3752000 20>, <3727000 15>,
				<3693000 10>, <3682000 5>, <3400000 0>;
	/* NTC 100k, Vref 1850mV, R pull-up 110K, R pull-down 1000k */
	voltage-temp-table = <1591473 750>, <1555286 800>, <1512176 850>,
				<1459276 900>, <1395886 950>, <1322179 1000>,
				<1238711 1050>, <1147116 1100>, <1049658 1150>,
				<949081 1200>, <848416 1250>, <750447 1300>,
				<657569 1350>, <571537 1400>, <493518 1450>,
				<423845 1500>, <362641 1550>, <309430 1600>,
				<263582 1650>, <221438 1700>, <188468 1750>;
	capacity-temp-table = <25 100>, <10 100>, <0 91>, <(-10) 86>, <(-20) 70>;
	resistance-temp-table = <25 100>, <10 157>, <0 1006>, <(-10) 1078>, <(-20) 1208>;

	/*sqc plan useless data*/
	charge-sdp-current-microamp = <700000 500000>;
	charge-dcp-current-microamp = <8000000 2000000>;
	charge-cdp-current-microamp = <8000000 1500000>;
	charge-unknown-current-microamp = <1000000 1000000>;
	charge-fchg-current-microamp = <8000000 4000000>;
	charge-flash-current-microamp = <8000000 4000000>;

	cap-calib-energy-density-ocv-table = <3350000 3800000>, <4150000 4350000>;
	cap-track-energy-density-ocv-table = <3400000 3722000>;

	dcp-jeita-temp-table = <1000 1030 0 4350000>,
				<1100 1130 1500000 4350000>,
				<1200 1230 1500000 4350000>,
				<1450 1420 3600000 4350000>,
				<1550 1520 1800000 4100000>;
	sdp-jeita-temp-table = <1000 1030 0 4350000>,
				<1100 1130 1500000 4350000>,
				<1200 1230 1500000 4350000>,
				<1450 1420 3600000 4350000>,
				<1550 1520 1800000 4100000>;
	cdp-jeita-temp-table = <1000 1030 0 4350000>,
				<1100 1130 1500000 4350000>,
				<1200 1230 1500000 4350000>,
				<1450 1420 3600000 4350000>,
				<1550 1520 1800000 4100000>;
	unknown-jeita-temp-table = <1000 1030 0 4350000>,
				<1100 1130 1500000 4350000>,
				<1200 1230 1500000 4350000>,
				<1450 1420 3600000 4350000>,
				<1550 1520 1800000 4100000>;
	fchg-jeita-temp-table = <1000 1030 0 4350000>,
				<1100 1130 1500000 4350000>,
				<1200 1230 1500000 4350000>,
				<1450 1420 3600000 4350000>,
				<1550 1520 1800000 4100000>;
	flash-jeita-temp-table = <1000 1030 0 4350000>,
				<1100 1130 1500000 4350000>,
				<1200 1230 1500000 4350000>,
				<1450 1420 3600000 4350000>,
				<1550 1520 1800000 4350000>;
};

&bat1_1 {
	compatible = "simple-battery";
	status = "okay";
	charge-term-current-microamp = <420000>;
	constant-charge-voltage-max-microvolt = <4468000>;
	constant-charge-current-max-microamp = <4600000>;
	factory-internal-resistance-micro-ohms = <115000>;
	voltage-min-design-microvolt = <3450000>;
	fast-charge-threshold-microvolt = <4100000>;
	fullbatt-voltage = <4368000>;		/* minus 100mV */
	fullbatt-current = <120000>;		/* not used */
	first-fullbatt-current = <150000>;
	fullbatt-track-end-vol = <4300000>;
	fullbatt-track-end-cur = <130000>;
	first-calib-voltage = <3680000>;
	first-calib-capacity = <50>;

	ir-cv-offset-microvolt = <100000>;
	ir-rc-micro-ohms = <20000>;
	ir-us-upper-limit-microvolt = <4500000>;

	batt-id-list = <110 430>;  /* kohm,  scud 5000mAh/highpower 6000mAh*/
	batt-id-ref-vol = <1875>; /* mV */
	charge-full-design-microamp-hours = <6000000>;
	/*Minimum Capacity 5880*0.96 = 5820,we use *0.975 */
	charge-full-microamp-hours = <5730000>;

	ocv-capacity-celsius = <25>;
	ocv-capacity-table-0 = <4413000 100>, <4355000 95>, <4306000 90>,
				<4250000 85>, <4191000 80>, <4131000 75>,
				<4075000 70>, <4024000 65>, <3977000 60>,
				<3924000 55>, <3871000 50>, <3841000 45>,
				<3816000 40>, <3796000 35>, <3780000 30>,
				<3763000 25>, <3741000 20>, <3716000 15>,
				<3684000 10>, <3673000 5>, <3400000 0>;
	/* NTC 100k, Vref 1850mV, R pull-up 110K, R pull-down 1000k */
	voltage-temp-table = <1591473 750>, <1555286 800>, <1512176 850>,
				<1459276 900>, <1395886 950>, <1322179 1000>,
				<1238711 1050>, <1147116 1100>, <1049658 1150>,
				<949081 1200>, <848416 1250>, <750447 1300>,
				<657569 1350>, <571537 1400>, <493518 1450>,
				<423845 1500>, <362641 1550>, <309430 1600>,
				<263582 1650>, <221438 1700>, <188468 1750>;
	capacity-temp-table = <25 100>, <10 100>, <0 91>, <(-10) 86>, <(-20) 70>;
	resistance-temp-table = <25 100>, <10 157>, <0 1006>, <(-10) 1078>, <(-20) 1208>;

	/*sqc plan useless data*/
	charge-sdp-current-microamp = <700000 500000>;
	charge-dcp-current-microamp = <8000000 2000000>;
	charge-cdp-current-microamp = <8000000 1500000>;
	charge-unknown-current-microamp = <1000000 1000000>;
	charge-fchg-current-microamp = <8000000 4000000>;
	charge-flash-current-microamp = <8000000 4000000>;

	cap-calib-energy-density-ocv-table = <3350000 3800000>, <4150000 4350000>;
	cap-track-energy-density-ocv-table = <3400000 3722000>;

	dcp-jeita-temp-table = <1000 1030 0 4350000>,
				<1100 1130 1500000 4350000>,
				<1200 1230 1500000 4350000>,
				<1450 1420 3600000 4350000>,
				<1550 1520 1800000 4100000>;
	sdp-jeita-temp-table = <1000 1030 0 4350000>,
				<1100 1130 1500000 4350000>,
				<1200 1230 1500000 4350000>,
				<1450 1420 3600000 4350000>,
				<1550 1520 1800000 4100000>;
	cdp-jeita-temp-table = <1000 1030 0 4350000>,
				<1100 1130 1500000 4350000>,
				<1200 1230 1500000 4350000>,
				<1450 1420 3600000 4350000>,
				<1550 1520 1800000 4100000>;
	unknown-jeita-temp-table = <1000 1030 0 4350000>,
				<1100 1130 1500000 4350000>,
				<1200 1230 1500000 4350000>,
				<1450 1420 3600000 4350000>,
				<1550 1520 1800000 4100000>;
	fchg-jeita-temp-table = <1000 1030 0 4350000>,
				<1100 1130 1500000 4350000>,
				<1200 1230 1500000 4350000>,
				<1450 1420 3600000 4350000>,
				<1550 1520 1800000 4100000>;
	flash-jeita-temp-table = <1000 1030 0 4350000>,
				<1100 1130 1500000 4350000>,
				<1200 1230 1500000 4350000>,
				<1450 1420 3600000 4350000>,
				<1550 1520 1800000 4350000>;
};

&bat1_2 {
	compatible = "simple-battery";
	status = "okay";
	charge-term-current-microamp = <420000>;
	constant-charge-voltage-max-microvolt = <4436000>;
	constant-charge-current-max-microamp = <4600000>;
	factory-internal-resistance-micro-ohms = <115000>;
	voltage-min-design-microvolt = <3450000>;
	fast-charge-threshold-microvolt = <4100000>;
	fullbatt-voltage = <4336000>;		/* minus 100mV */
	fullbatt-current = <120000>;		/* not used */
	first-fullbatt-current = <150000>;
	fullbatt-track-end-vol = <4300000>;
	fullbatt-track-end-cur = <130000>;
	first-calib-voltage = <3680000>;
	first-calib-capacity = <50>;

	ir-cv-offset-microvolt = <100000>;
	ir-rc-micro-ohms = <20000>;
	ir-us-upper-limit-microvolt = <4500000>;

	batt-id-list = <110 430>;  /* kohm,  scud 5000mAh/highpower 6000mAh*/
	batt-id-ref-vol = <1875>; /* mV */
	charge-full-design-microamp-hours = <6000000>;
	/*Minimum Capacity 5880*0.96 = 5820,we use *0.975 */
	charge-full-microamp-hours = <5730000>;

	ocv-capacity-celsius = <25>;
	ocv-capacity-table-0 = <4381000 100>, <4325000 95>, <4277000 90>,
				<4223000 85>, <4166000 80>, <4108000 75>,
				<4054000 70>, <4004000 65>, <3959000 60>,
				<3907000 55>, <3856000 50>, <3827000 45>,
				<3803000 40>, <3783000 35>, <3768000 30>,
				<3752000 25>, <3730000 20>, <3706000 15>,
				<3675000 10>, <3664000 5>, <3400000 0>;
	/* NTC 100k, Vref 1850mV, R pull-up 110K, R pull-down 1000k */
	voltage-temp-table = <1591473 750>, <1555286 800>, <1512176 850>,
				<1459276 900>, <1395886 950>, <1322179 1000>,
				<1238711 1050>, <1147116 1100>, <1049658 1150>,
				<949081 1200>, <848416 1250>, <750447 1300>,
				<657569 1350>, <571537 1400>, <493518 1450>,
				<423845 1500>, <362641 1550>, <309430 1600>,
				<263582 1650>, <221438 1700>, <188468 1750>;
	capacity-temp-table = <25 100>, <10 100>, <0 91>, <(-10) 86>, <(-20) 70>;
	resistance-temp-table = <25 100>, <10 157>, <0 1006>, <(-10) 1078>, <(-20) 1208>;

	/*sqc plan useless data*/
	charge-sdp-current-microamp = <700000 500000>;
	charge-dcp-current-microamp = <8000000 2000000>;
	charge-cdp-current-microamp = <8000000 1500000>;
	charge-unknown-current-microamp = <1000000 1000000>;
	charge-fchg-current-microamp = <8000000 4000000>;
	charge-flash-current-microamp = <8000000 4000000>;

	cap-calib-energy-density-ocv-table = <3350000 3800000>, <4150000 4350000>;
	cap-track-energy-density-ocv-table = <3400000 3722000>;

	dcp-jeita-temp-table = <1000 1030 0 4350000>,
				<1100 1130 1500000 4350000>,
				<1200 1230 1500000 4350000>,
				<1450 1420 3600000 4350000>,
				<1550 1520 1800000 4100000>;
	sdp-jeita-temp-table = <1000 1030 0 4350000>,
				<1100 1130 1500000 4350000>,
				<1200 1230 1500000 4350000>,
				<1450 1420 3600000 4350000>,
				<1550 1520 1800000 4100000>;
	cdp-jeita-temp-table = <1000 1030 0 4350000>,
				<1100 1130 1500000 4350000>,
				<1200 1230 1500000 4350000>,
				<1450 1420 3600000 4350000>,
				<1550 1520 1800000 4100000>;
	unknown-jeita-temp-table = <1000 1030 0 4350000>,
				<1100 1130 1500000 4350000>,
				<1200 1230 1500000 4350000>,
				<1450 1420 3600000 4350000>,
				<1550 1520 1800000 4100000>;
	fchg-jeita-temp-table = <1000 1030 0 4350000>,
				<1100 1130 1500000 4350000>,
				<1200 1230 1500000 4350000>,
				<1450 1420 3600000 4350000>,
				<1550 1520 1800000 4100000>;
	flash-jeita-temp-table = <1000 1030 0 4350000>,
				<1100 1130 1500000 4350000>,
				<1200 1230 1500000 4350000>,
				<1450 1420 3600000 4350000>,
				<1550 1520 1800000 4350000>;
};

&bat1_3 {
	compatible = "simple-battery";
	status = "okay";
	charge-term-current-microamp = <420000>;
	constant-charge-voltage-max-microvolt = <4336000>;
	constant-charge-current-max-microamp = <4600000>;
	factory-internal-resistance-micro-ohms = <115000>;
	voltage-min-design-microvolt = <3450000>;
	fast-charge-threshold-microvolt = <4100000>;
	fullbatt-voltage = <4236000>;		/* minus 100mV */
	fullbatt-current = <120000>;		/* not used */
	first-fullbatt-current = <150000>;
	fullbatt-track-end-vol = <4300000>;
	fullbatt-track-end-cur = <130000>;
	first-calib-voltage = <3680000>;
	first-calib-capacity = <50>;

	ir-cv-offset-microvolt = <100000>;
	ir-rc-micro-ohms = <20000>;
	ir-us-upper-limit-microvolt = <4500000>;

	batt-id-list = <110 430>;  /* kohm,  scud 5000mAh/highpower 6000mAh*/
	batt-id-ref-vol = <1875>; /* mV */
	charge-full-design-microamp-hours = <6000000>;
	/*Minimum Capacity 5880*0.96 = 5820,we use *0.975 */
	charge-full-microamp-hours = <5730000>;

	ocv-capacity-celsius = <25>;
	ocv-capacity-table-0 = <4281000 100>, <4231000 95>, <4188000 90>,
				<4139000 85>, <4087000 80>, <4036000 75>,
				<3987000 70>, <3942000 65>, <3902000 60>,
				<3856000 55>, <3809000 50>, <3783000 45>,
				<3762000 40>, <3744000 35>, <3731000 30>,
				<3716000 25>, <3696000 20>, <3675000 15>,
				<3647000 10>, <3637000 5>, <3400000 0>;
	/* NTC 100k, Vref 1850mV, R pull-up 110K, R pull-down 1000k */
	voltage-temp-table = <1591473 750>, <1555286 800>, <1512176 850>,
				<1459276 900>, <1395886 950>, <1322179 1000>,
				<1238711 1050>, <1147116 1100>, <1049658 1150>,
				<949081 1200>, <848416 1250>, <750447 1300>,
				<657569 1350>, <571537 1400>, <493518 1450>,
				<423845 1500>, <362641 1550>, <309430 1600>,
				<263582 1650>, <221438 1700>, <188468 1750>;
	capacity-temp-table = <25 100>, <10 100>, <0 91>, <(-10) 86>, <(-20) 70>;
	resistance-temp-table = <25 100>, <10 157>, <0 1006>, <(-10) 1078>, <(-20) 1208>;

	/*sqc plan useless data*/
	charge-sdp-current-microamp = <700000 500000>;
	charge-dcp-current-microamp = <8000000 2000000>;
	charge-cdp-current-microamp = <8000000 1500000>;
	charge-unknown-current-microamp = <1000000 1000000>;
	charge-fchg-current-microamp = <8000000 4000000>;
	charge-flash-current-microamp = <8000000 4000000>;

	cap-calib-energy-density-ocv-table = <3350000 3800000>, <4150000 4350000>;
	cap-track-energy-density-ocv-table = <3400000 3722000>;

	dcp-jeita-temp-table = <1000 1030 0 4350000>,
				<1100 1130 1500000 4350000>,
				<1200 1230 1500000 4350000>,
				<1450 1420 3600000 4350000>,
				<1550 1520 1800000 4100000>;
	sdp-jeita-temp-table = <1000 1030 0 4350000>,
				<1100 1130 1500000 4350000>,
				<1200 1230 1500000 4350000>,
				<1450 1420 3600000 4350000>,
				<1550 1520 1800000 4100000>;
	cdp-jeita-temp-table = <1000 1030 0 4350000>,
				<1100 1130 1500000 4350000>,
				<1200 1230 1500000 4350000>,
				<1450 1420 3600000 4350000>,
				<1550 1520 1800000 4100000>;
	unknown-jeita-temp-table = <1000 1030 0 4350000>,
				<1100 1130 1500000 4350000>,
				<1200 1230 1500000 4350000>,
				<1450 1420 3600000 4350000>,
				<1550 1520 1800000 4100000>;
	fchg-jeita-temp-table = <1000 1030 0 4350000>,
				<1100 1130 1500000 4350000>,
				<1200 1230 1500000 4350000>,
				<1450 1420 3600000 4350000>,
				<1550 1520 1800000 4100000>;
	flash-jeita-temp-table = <1000 1030 0 4350000>,
				<1100 1130 1500000 4350000>,
				<1200 1230 1500000 4350000>,
				<1450 1420 3600000 4350000>,
				<1550 1520 1800000 4350000>;
};

&cm {
	compatible = "charger-manager";
	status = "okay";
	cm-name = "battery";
	cm-poll-mode = <2>;
	cm-poll-interval = <15000>;
	cm-battery-stat = <2>;

	cm-fullbatt-vchkdrop-ms = <30000>;
	cm-fullbatt-vchkdrop-volt = <60000>;
	cm-fullbatt-capacity = <100>;
	/*Charge pump target charge current*/
	cm-cp-taper-current = <1000000>;

	cm-chargers = "charger_psy";
	zte-cm-charger = "zte_charger_psy";
	zte-cm-fuel-gauge = "zte-fgu";

	cm-fuel-gauge = "sc27xx-fgu";

	/* in deci centigrade */
	cm-battery-cold = <200>;
	cm-battery-cold-in-minus;
	cm-battery-hot = <800>;
	cm-battery-temp-diff = <100>;

	/* Allow charging for 6hr */
	cm-charging-max = <21600000>;
	/* recovery charging after stop charging 45min */
	cm-discharging-max = <2700000>;

	/* the interval to feed charger watchdog */
	cm-wdt-interval = <60>;

	/* drop voltage in microVolts to allow shutdown */
	cm-shutdown-voltage = <3100000>;

	/* when 99% of the time is exceeded, it will be forced to 100% */
	cm-tickle-time-out = <1500>;

	/* how much time to allow capacity change */
	cm-one-cap-time = <30>;

	/* because kernel not load thermal-gerneric-adc.ko in charger mode, then battery uevent can't broadcast to ztecharger */
	/* cm-thermal-zone = "board-thmzone"; */

	/* when the safe charging voltage is exceeded, stop charging */
	cm-charge-voltage-max = <6500000>;
	cm-fast-charge-voltage-max = <10500000>;
	cm-flash-charge-voltage-max = <12000000>;
	/* drop voltage in microVolts to restart charging */
	cm-charge-voltage-drop = <700000>;
	cm-fast-charge-voltage-drop = <700000>;
	cm-flash-charge-voltage-drop = <1000000>;

	/* sprd_fchg parameter */
	sprd,support-fchg;
	sprd,support-pd-pps;
	sprd,pd-fixed-max-microwatt = <18000000>;

	monitored-battery-0 = <&bat0_0 &bat0_1 &bat0_2 &bat0_3>;
	monitored-battery-1 = <&bat1_0 &bat1_1 &bat1_2 &bat1_3>;
	cm-capacity-track;
	cm-keep-awake;

	phys = <&ssphy>;
	pd-extcon-enable;
	extcon = <&pmic_typec>, <&pmic_pd>;
	use-typec-extcon;
};

/ {
	zte_misc: zte_misc {
		status = "okay";
		compatible = "zte-misc";
	};
};

&i2c6 {
	#address-cells = <1>;
	#size-cells = <0>;

	status = "okay";
	bq2560x_chg: charger@6b {
		compatible = "ti,bq2560x_chg";
		reg = <0x6b>;
		phys = <&ssphy>;
		monitored-battery-0 = <&bat0_0 &bat0_1 &bat0_2 &bat0_3>;
		monitored-battery-1 = <&bat1_0 &bat1_1 &bat1_2 &bat1_3>;
		extcon = <&pmic_typec>;
		vindpm-value = <4270>;
		use-typec-extcon;
		vddvbus:otg-vbus {
			regulator-name = "vddvbus";
		};
	};
};

&i2c6 {
	status = "okay";
	nu2115-standalone@6d {
		compatible = "nu2115-standalone";
		status = "okay";
		reg = <0x6d>;
		gpio_int = <&ap_gpio 59 0x0>;
		extcon = <&pmic_typec>;
	};
};

&i2c6 {
    sc8541@6a{
        compatible = "sc,sc8541-standalone";
        reg = <0x6a>;
        sc8541,intr_gpio = <&ap_gpio 59 0x0>;
        extcon = <&pmic_typec>;

        charger_name = "primary_dvchg";
        sc,sc8541,vbat-ovp-dis = <0>;
        sc,sc8541,vbat-ovp = <90>; /*3840 + val * 10*/
        sc,sc8541,vbat-ovp-alm-dis = <1>;
        sc,sc8541,vbat-ovp-alm = <70>; /*3840 + val * 10*/
        sc,sc8541,ibat-ocp-dis = <0>;
        sc,sc8541,ibat-ocp  = <81>; /*val * 100*/
        sc,sc8541,ibat-ocp-alm-dis = <1>;
        sc,sc8541,ibat-ocp-alm = <80>; /*val * 100*/
        sc,sc8541,ibus-ucp-dis = <0>;
        sc,sc8541,vbus-in-range-dis = <0>;
        sc,sc8541,vbus-pd-en = <0>;
        sc,sc8541,vbus-ovp = <38>; /*7000 + val * 50*/
        sc,sc8541,vbus-ovp-alm-dis = <1>;
        sc,sc8541,vbus-ovp-alm = <34>; /*7000 + val * 50*/
        sc,sc8541,ibus-ocp-dis = <0>;
        sc,sc8541,ibus-ocp = <13>; /*1000 + val * 250*/
        sc,sc8541,tshut-dis = <1>;
        sc,sc8541,tsbus-flt-dis = <1>;
        sc,sc8541,tsbat-flt-dis = <1>;
        sc,sc8541,tdie-alm = <200>; /*25 + val * 0.5*/
        sc,sc8541,tsbus-flt = <21>;
        sc,sc8541,tsbat-flt = <21>;
        sc,sc8541,vac1-ovp = <2>; /*0:6.5V 1:10.5V 2:12V 3:14V 4:16V 5~7:18V*/
        sc,sc8541,vac2-ovp = <2>; /*0:6.5V 1:10.5V 2:12V 3:14V 4:16V 5~7:18V*/
        sc,sc8541,vac1-pd-en = <0>;
        sc,sc8541,vac2-pd-en = <0>;
        sc,sc8541,fsw-set = <4>; /*0:200KHz 1:300KHz 2:400KHz 
                    3:500KHz 4:600KHz 5:650KHz 6:700KHz 7:750KHz*/
        sc,sc8541,wd-timeout = <0>; /*0:0.5s 1:1s 2:5s 3:30s*/
        sc,sc8541,wd-timeout-dis = <1>;
        sc,sc8541,ibat-sns-r = <0>; /*0:2mho 1:5mho*/
        sc,sc8541,ss-timeout = <7>; /*0:6.25ms 1:12.5ms 2:25ms 3:50ms 
                    4:100ms 5:400ms 6:1.5s 7:10s*/
        sc,sc8541,ibus-ucp-fall-dg = <1>;
        sc,sc8541,vout-ovp-dis = <0>;
        sc,sc8541,vout-ovp = <3>; /*4700 + val * 100*/
        sc,sc8541,ms = <0>; /*standalone*/
        sc,sc8541,pmid2out-uvp = <7>; /*50 + val * 25*/
        sc,sc8541,pmid2out-ovp = <7>; /*150 + val * 50*/
    };
};

&pmic_fgu {
	monitored-battery-0 = <&bat0_0 &bat0_1 &bat0_2 &bat0_3>;
	monitored-battery-1 = <&bat1_0 &bat1_1 &bat1_2 &bat1_3>;
	fgu-cap-remap-table = <10 11 4>, <11 12 3>, <98 99 2>, <99 100 5>;
	sprd,calib-resistance-micro-ohms = <3000>;
	sprd,comp-resistance-mohm = <11>;
	io-channels = <&pmic_adc 6>, <&pmic_adc 0>, <&pmic_adc 14>;
	io-channel-names = "adc-batt-id", "bat-temp", "charge-vol";
	fgu-capacity-track;
	phys = <&ssphy>;

	sprd,relax-counter-threshold = <580>;
	sprd,relax-current-threshold = <30>;
	sprd,capacity-sleep-calibration;

	/*sprd,bat-aging;*/
	bat-0-aging-cycles = <0>, <100>, <300>, <1000>;
	bat-0-aging-fcc-uah = <4500000>, <4359000>, <4219000>, <3780000>;
	bat-1-aging-cycles = <0>, <100>, <300>, <800>;
	bat-1-aging-fcc-uah = <5640000>, <5467000>, <5294000>, <4754000>;


	sprd,capacity-boot-calibration;
	extcon = <&pmic_typec>;
	sprd,zte-low-temp-algo;
	use-typec-extcon;
};

&pmic_fchg {
	status = "disabled";
	phys = <&ssphy>;
	sprd,input-voltage-microvolt = <5000000>;
};

&pmic_pd {
	status = "okay";
	vbus-supply = <&vddvbus>;
	use-pdhub-c2c;
	sprd,syscon-aon-apb = <&aon_apb_regs>;
	usb_con: connector {
		compatible = "usb-c-connector";
		label = "USB-C";
		power-role = "dual";
		try-power-role = "sink";
		source-pdos = <PDO_FIXED(5000, 1000, PDO_FIXED_USB_COMM | PDO_FIXED_SUSPEND |
			                 PDO_FIXED_DUAL_ROLE | PDO_FIXED_DATA_SWAP)>;			   
		sink-pdos = <PDO_FIXED(5000, 3000, PDO_FIXED_USB_COMM | PDO_FIXED_DUAL_ROLE |
				       PDO_FIXED_DATA_SWAP)
				PDO_PPS_APDO(3300, 11000, 6000)>;
		op-sink-microwatt = <10000000>;

		sprd,support-pd-cts;
	};
};

#include "../bat_setting/battery_protect_policy_080509200178.dtsi"
